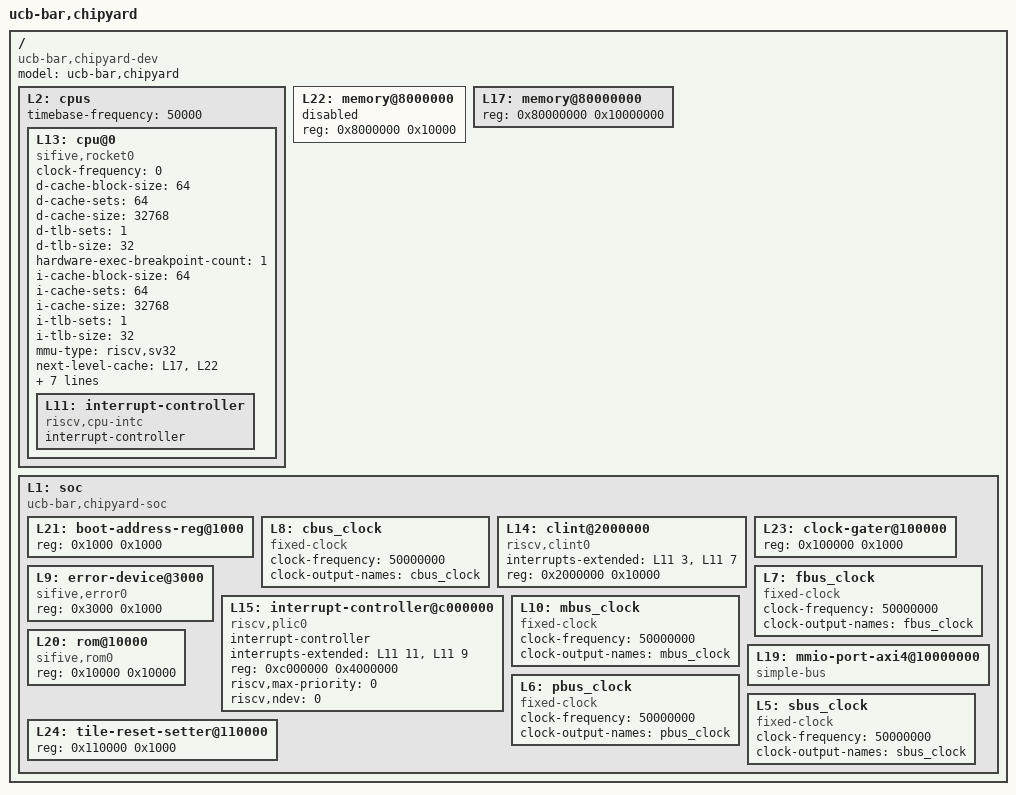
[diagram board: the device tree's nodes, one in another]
/dts-v1/;

/ {
	#address-cells = <1>;
	#size-cells = <1>;
	compatible = "ucb-bar,chipyard-dev";
	model = "ucb-bar,chipyard";
	L2: cpus {
		#address-cells = <1>;
		#size-cells = <0>;
		timebase-frequency = <50000>;
		L13: cpu@0 {
			clock-frequency = <0>;
			compatible = "sifive,rocket0", "riscv";
			d-cache-block-size = <64>;
			d-cache-sets = <64>;
			d-cache-size = <32768>;
			d-tlb-sets = <1>;
			d-tlb-size = <32>;
			device_type = "cpu";
			hardware-exec-breakpoint-count = <1>;
			i-cache-block-size = <64>;
			i-cache-sets = <64>;
			i-cache-size = <32768>;
			i-tlb-sets = <1>;
			i-tlb-size = <32>;
			mmu-type = "riscv,sv32";
			next-level-cache = <&L17 &L22>;
			reg = <0x0>;
			riscv,isa = "rv32imafcbzicsr_zifencei_zihpm_zfh_zba_zbb_zbs_xrocket";
			riscv,pmpgranularity = <4>;
			riscv,pmpregions = <8>;
			status = "okay";
			timebase-frequency = <50000>;
			tlb-split;
			L11: interrupt-controller {
				#interrupt-cells = <1>;
				compatible = "riscv,cpu-intc";
				interrupt-controller;
			};
		};
	};
	L22: memory@8000000 {
		device_type = "memory";
		reg = <0x8000000 0x10000>;
		status = "disabled";
	};
	L17: memory@80000000 {
		device_type = "memory";
		reg = <0x80000000 0x10000000>;
	};
	L1: soc {
		#address-cells = <1>;
		#size-cells = <1>;
		compatible = "ucb-bar,chipyard-soc", "simple-bus";
		ranges;
		L21: boot-address-reg@1000 {
			reg = <0x1000 0x1000>;
			reg-names = "control";
		};
		L8: cbus_clock {
			#clock-cells = <0>;
			clock-frequency = <50000000>;
			clock-output-names = "cbus_clock";
			compatible = "fixed-clock";
		};
		L14: clint@2000000 {
			compatible = "riscv,clint0";
			interrupts-extended = <&L11 3 &L11 7>;
			reg = <0x2000000 0x10000>;
			reg-names = "control";
		};
		L23: clock-gater@100000 {
			reg = <0x100000 0x1000>;
			reg-names = "control";
		};
		L9: error-device@3000 {
			compatible = "sifive,error0";
			reg = <0x3000 0x1000>;
		};
		L7: fbus_clock {
			#clock-cells = <0>;
			clock-frequency = <50000000>;
			clock-output-names = "fbus_clock";
			compatible = "fixed-clock";
		};
		L15: interrupt-controller@c000000 {
			#interrupt-cells = <1>;
			compatible = "riscv,plic0";
			interrupt-controller;
			interrupts-extended = <&L11 11 &L11 9>;
			reg = <0xc000000 0x4000000>;
			reg-names = "control";
			riscv,max-priority = <0>;
			riscv,ndev = <0>;
		};
		L10: mbus_clock {
			#clock-cells = <0>;
			clock-frequency = <50000000>;
			clock-output-names = "mbus_clock";
			compatible = "fixed-clock";
		};
		L19: mmio-port-axi4@10000000 {
			#address-cells = <1>;
			#size-cells = <1>;
			compatible = "simple-bus";
			ranges = <0x10000000 0x10000000 0x20000000>;
		};
		L6: pbus_clock {
			#clock-cells = <0>;
			clock-frequency = <50000000>;
			clock-output-names = "pbus_clock";
			compatible = "fixed-clock";
		};
		L20: rom@10000 {
			compatible = "sifive,rom0";
			reg = <0x10000 0x10000>;
			reg-names = "mem";
		};
		L5: sbus_clock {
			#clock-cells = <0>;
			clock-frequency = <50000000>;
			clock-output-names = "sbus_clock";
			compatible = "fixed-clock";
		};
		L24: tile-reset-setter@110000 {
			reg = <0x110000 0x1000>;
			reg-names = "control";
		};
	};
};
